# MSPM0G350X register map
Vendor: Texas Instruments; File version: This preliminary header file does not have a version number - build date: 2023-02-21 16:25:48
CPU: CM0 r0p1, little endian, MPU, no FPU, 3 interrupt priority bits
Registers are 32-bit, read-write, reset 0x0 unless marked. A register's access mark holds for its fields unless they carry their own. Offsets are from the block's base; [hi:lo] are bit positions; {n}, {i} and the like mark numbered series.

## CANFD0 (part 1 of 2) — PERIPHERALREGION
Base 0x40508000
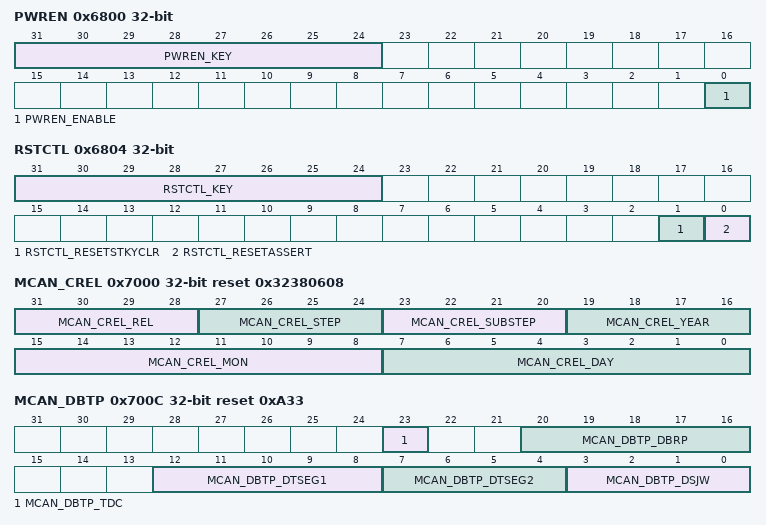
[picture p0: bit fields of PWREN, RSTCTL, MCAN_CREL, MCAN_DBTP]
0x6800 PWREN — Power enable
  [31:24] PWREN_KEY wo — KEY to allow Power State Change
    38=PWREN_KEY_UNLOCK_W (_TO_UNLOCK_W_)
  [0] PWREN_ENABLE — Enable the power
    0=PWREN_ENABLE_DISABLE (DISABLE); 1=PWREN_ENABLE_ENABLE (ENABLE)
0x6804 RSTCTL wo — Reset Control
  [31:24] RSTCTL_KEY — Unlock key
    177=RSTCTL_KEY_UNLOCK_W (_TO_UNLOCK_W_)
  [1] RSTCTL_RESETSTKYCLR — Clear the RESETSTKY bit in the STAT register
    0=RSTCTL_RESETSTKYCLR_NOP (NOP); 1=RSTCTL_RESETSTKYCLR_CLR (CLR)
  [0] RSTCTL_RESETASSERT — Assert reset to the peripheral
    0=RSTCTL_RESETASSERT_NOP (NOP); 1=RSTCTL_RESETASSERT_ASSERT (ASSERT)
0x6814 STAT ro — Status Register
  [16] STAT_RESETSTKY — This bit indicates, if the peripheral was reset, since this bit was cleared by RESETSTKYCLR in the RSTCTL register
    0=STAT_RESETSTKY_NORES (NORES); 1=STAT_RESETSTKY_RESET (RESET)
0x7000 MCAN_CREL ro reset 0x32380608 — MCAN Core Release Register
  [31:28] MCAN_CREL_REL — Core Release. One digit, BCD-coded.
  [27:24] MCAN_CREL_STEP — Step of Core Release. One digit, BCD-coded.
  [23:20] MCAN_CREL_SUBSTEP — Sub-Step of Core Release. One digit, BCD-coded.
  [19:16] MCAN_CREL_YEAR — Time Stamp Year. One digit, BCD-coded.
  [15:8] MCAN_CREL_MON — Time Stamp Month. Two digits, BCD-coded.
  [7:0] MCAN_CREL_DAY — Time Stamp Day. Two digits, BCD-coded.
0x7004 MCAN_ENDN ro reset 0x87654321 — MCAN Endian Register
  [31:0] MCAN_ENDN_ETV — Endianess Test Value. Reading the constant value maintained in this register allows software to determine the endianess of the host CPU.
0x700C MCAN_DBTP reset 0xA33 — MCAN Data Bit Timing and Prescaler Register
  [23] MCAN_DBTP_TDC — Transmitter Delay Compensation 0 Transmitter Delay Compensation disabled 1 Transmitter Delay Compensation enabled +I107
  [20:16] MCAN_DBTP_DBRP — Data Bit Rate Prescaler. The value by which the oscillator frequency is divided for generating the bit time quanta. The bit time is built up from a multiple of this quanta. Valid values for the Bit Rate Prescaler are 0 to 31. The actual interpretation by the hardware of this value is such that one more than the value programmed here is used. Qualified Write is possible only with CCCR.CCE='1' and CCCR.INIT='1'.
  [12:8] MCAN_DBTP_DTSEG1 — Data Time Segment Before Sample Point. Valid values are 0 to 31. The actual interpretation by the hardware of this value is such that one more than the programmed value is used. Qualified Write is possible only with CCCR.CCE='1' and CCCR.INIT='1'.
  [7:4] MCAN_DBTP_DTSEG2 — Data Time Segment After Sample Point. Valid values are 0 to 15. The actual interpretation by the hardware of this value is such that one more than the programmed value is used. Qualified Write is possible only with CCCR.CCE='1' and CCCR.INIT='1'.
  [3:0] MCAN_DBTP_DSJW — Data Resynchronization Jump Width. Valid values are 0 to 15. The actual interpretation by the hardware of this value is such that one more than the value programmed here is used. Qualified Write is possible only with CCCR.CCE='1' and CCCR.INIT='1'.
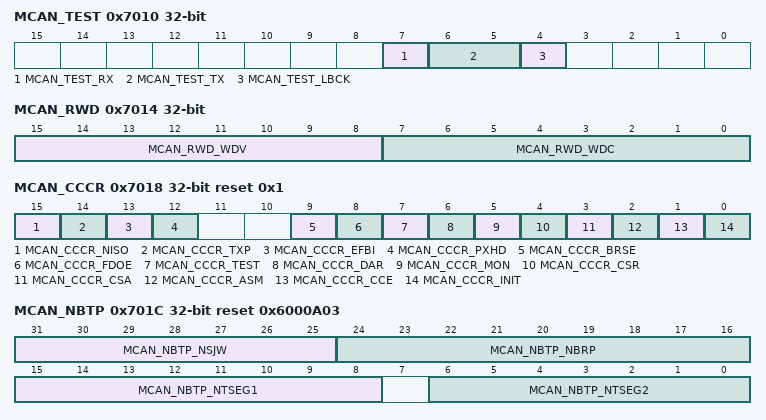
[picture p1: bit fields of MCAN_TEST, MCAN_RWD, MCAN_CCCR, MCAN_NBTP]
0x7010 MCAN_TEST (reset mask 0xFFFFFF7F)
  [7] MCAN_TEST_RX ro — Receive Pin. Monitors the actual value of the CAN receive pin. 0 The CAN bus is dominant (CAN RX pin = '0') 1 The CAN bus is recessive (CAN RX pin = '1')
  [6:5] MCAN_TEST_TX — Control of Transmit Pin 00 CAN TX pin controlled by the CAN Core, updated at the end of the CAN bit time 01 Sample Point can be monitored at CAN TX pin 10 Dominant ('0') level at CAN TX pin 11 Recessive ('1') at CAN TX pin Qualified Write is possible only with CCCR.CCE='1' and CCCR.INIT='1'.
  [4] MCAN_TEST_LBCK — Loop Back Mode 0 Reset value, Loop Back Mode is disabled 1 Loop Back Mode is enabled Qualified Write is possible only with CCCR.CCE='1' and CCCR.INIT='1'.
0x7014 MCAN_RWD — MCAN RAM Watchdog
  [15:8] MCAN_RWD_WDV ro — Watchdog Value. Acutal Message RAM Watchdog Counter Value. The RAM Watchdog monitors the READY output of the Message RAM. A Message RAM access via the MCAN's Generic Master Interface starts the Message RAM Watchdog Counter with the value configured by the WDC field. The counter is reloaded with WDC when the Message RAM signals successful completion by activating its READY output. In case there is no response from the Message RAM until the counter has counted down to zero, the counter stops and interrupt flag MCAN_IR.WDI is set. The RAM Watchdog Counter is clocked by the host (system) clock.
  [7:0] MCAN_RWD_WDC — Watchdog Configuration. Start value of the Message RAM Watchdog Counter. With the reset value of &quot;00&quot; the counter is disabled. Qualified Write is possible only with CCCR.CCE='1' and CCCR.INIT='1'.
0x7018 MCAN_CCCR reset 0x1 — MCAN CC Control Register
  [15] MCAN_CCCR_NISO — Non ISO Operation. If this bit is set, the MCAN uses the CAN FD frame format as specified by the Bosch CAN FD Specification V1.0. 0 CAN FD frame format according to ISO 11898-1:2015 1 CAN FD frame format according to Bosch CAN FD Specification V1.0
  [14] MCAN_CCCR_TXP — Transmit Pause. If this bit is set, the MCAN pauses for two CAN bit times before starting the next transmission after itself has successfully transmitted a frame. 0 Transmit pause disabled 1 Transmit pause enabled Qualified Write is possible only with CCCR.CCE='1' and CCCR.INIT='1'.
  [13] MCAN_CCCR_EFBI — Edge Filtering during Bus Integration 0 Edge filtering disabled 1 Two consecutive dominant tq required to detect an edge for hard synchronization Qualified Write is possible only with CCCR.CCE='1' and CCCR.INIT='1'.
  [12] MCAN_CCCR_PXHD — Protocol Exception Handling Disable 0 Protocol exception handling enabled 1 Protocol exception handling disabled Note: When protocol exception handling is disabled, the MCAN will transmit an error frame when it detects a protocol exception condition. Qualified Write is possible only with CCCR.CCE='1' and CCCR.INIT='1'.
  [9] MCAN_CCCR_BRSE — Bit Rate Switch Enable 0 Bit rate switching for transmissions disabled 1 Bit rate switching for transmissions enabled Note: When CAN FD operation is disabled FDOE = '0', BRSE is not evaluated. Qualified Write is possible only with CCCR.CCE='1' and CCCR.INIT='1'.
  [8] MCAN_CCCR_FDOE — Flexible Datarate Operation Enable 0 FD operation disabled 1 FD operation enabled Qualified Write is possible only with CCCR.CCE='1' and CCCR.INIT='1'.
  [7] MCAN_CCCR_TEST — Test Mode Enable 0 Normal operation, register TEST holds reset values 1 Test Mode, write access to register TEST enabled Qualified Write 1 to Set is possible only with CCCR.CCE='1' and CCCR.INIT='1'.
  [6] MCAN_CCCR_DAR — Disable Automatic Retransmission 0 Automatic retransmission of messages not transmitted successfully enabled 1 Automatic retransmission disabled Qualified Write is possible only with CCCR.CCE='1' and CCCR.INIT='1'.
  [5] MCAN_CCCR_MON — Bus Monitoring Mode. Bit MON can only be set by SW when both CCE and INIT are set to '1'. The bit can be reset by SW at any time. 0 Bus Monitoring Mode is disabled 1 Bus Monitoring Mode is enabled Qualified Write 1 to Set is possible only with CCCR.CCE='1' and CCCR.INIT='1'.
  [4] MCAN_CCCR_CSR — Clock Stop Request 0 No clock stop is requested 1 Clock stop requested. When clock stop is requested, first INIT and then CSA will be set after all pending transfer requests have been completed and the CAN bus reached idle.
  [3] MCAN_CCCR_CSA ro — Clock Stop Acknowledge 0 No clock stop acknowledged 1 MCAN may be set in power down by stopping the Host and CAN clocks
  [2] MCAN_CCCR_ASM — Restricted Operation Mode. Bit ASM can only be set by SW when both CCE and INIT are set to '1'. The bit can be reset by SW at any time. 0 Normal CAN operation 1 Restricted Operation Mode active Qualified Write 1 to Set is possible only with CCCR.CCE='1' and CCCR.INIT='1'.
  [1] MCAN_CCCR_CCE — Configuration Change Enable 0 The CPU has no write access to the protected configuration registers 1 The CPU has write access to the protected configuration registers (while CCCR.INIT = '1') Qualified Write is possible only with CCCR.CCE='1' and CCCR.INIT='1'.
  [0] MCAN_CCCR_INIT — Initialization 0 Normal Operation 1 Initialization is started Note: Due to the synchronization mechanism between the two clock domains, there may be a delay until the value written to INIT can be read back. Therefore the programmer has to assure that the previous value written to INIT has been accepted by reading INIT before setting INIT to a new value.
0x701C MCAN_NBTP reset 0x6000A03 — MCAN Nominal Bit Timing and Prescaler Register
  [31:25] MCAN_NBTP_NSJW — Nominal (Re)Synchronization Jump Width. Valid values are 0 to 127. The actual interpretation by the hardware of this value is such that one more than the value programmed here is used. Qualified Write is possible only with CCCR.CCE='1' and CCCR.INIT='1'.
  [24:16] MCAN_NBTP_NBRP — Nominal Bit Rate Prescaler. The value by which the oscillator frequency is divided for generating the bit time quanta. The bit time is built up from a multiple of this quanta. Valid values for the Bit Rate Prescaler are 0 to 511. The actual interpretation by the hardware of this value is such that one more than the value programmed here is used. Qualified Write is possible only with CCCR.CCE='1' and CCCR.INIT='1'.
  [15:8] MCAN_NBTP_NTSEG1 — Nominal Time Segment Before Sample Point. Valid values are 1 to 255. The actual interpretation by the hardware of this value is such that one more than the programmed value is used. Qualified Write is possible only with CCCR.CCE='1' and CCCR.INIT='1'.
  [6:0] MCAN_NBTP_NTSEG2 — Nominal Time Segment After Sample Point. Valid values are 1 to 127. The actual interpretation by the hardware of this value is such that one more than the programmed value is used. Qualified Write is possible only with CCCR.CCE='1' and CCCR.INIT='1'.
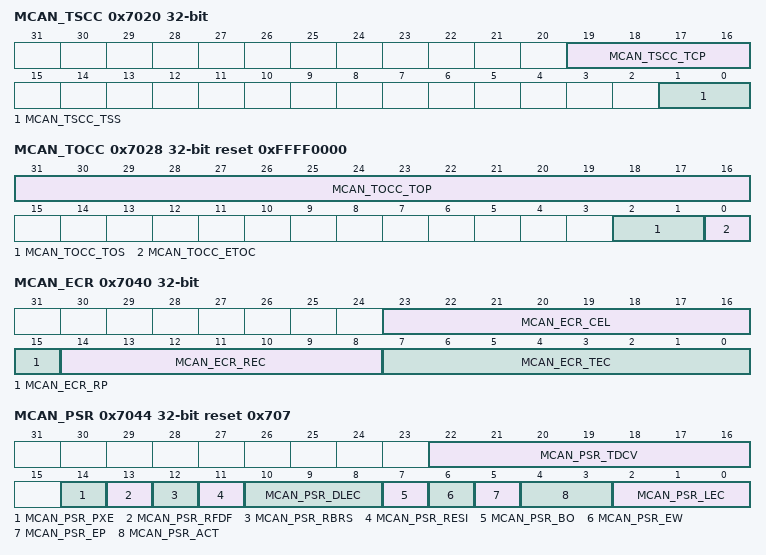
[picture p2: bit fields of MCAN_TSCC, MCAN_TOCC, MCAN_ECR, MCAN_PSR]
0x7020 MCAN_TSCC — MCAN Timestamp Counter Configuration
  [19:16] MCAN_TSCC_TCP — Timestamp Counter Prescaler. Configures the timestamp and timeout counters time unit in multiples of CAN bit times. Valid values are 0 to 15. The actual interpretation by the hardware of this value is such that one more than the value programmed here is used. Note: With CAN FD an external counter is required for timestamp generation (TSS = &quot;10&quot;). Qualified Write is possible only with CCCR.CCE='1' and CCCR.INIT='1'.
  [1:0] MCAN_TSCC_TSS — Timestamp Select 00 Timestamp counter value always 0x0000 01 Timestamp counter value incremented according to TCP 10 External timestamp counter value used 11 Same as &quot;00&quot; Qualified Write is possible only with CCCR.CCE='1' and CCCR.INIT='1'.
0x7024 MCAN_TSCV — MCAN Timestamp Counter Value
  [15:0] MCAN_TSCV_TSC — Timestamp Counter. The internal/external Timestamp Counter value is captured on start of frame (both Rx and Tx). When TSCC.TSS = &quot;01&quot;, the Timestamp Counter is incremented in multiples of CAN bit times, (1...16), depending on the configuration of TSCC.TCP. A wrap around sets interrupt flag IR.TSW. Write access resets the counter to zero. When TSCC.TSS = &quot;10&quot;, TSC reflects the External Timestamp Counter value, and a write access has no impact. Note: A &quot;wrap around&quot; is a change of the Timestamp Counter value from non-zero to zero not caused by write access to MCAN_TSCV.
0x7028 MCAN_TOCC reset 0xFFFF0000 — MCAN Timeout Counter Configuration
  [31:16] MCAN_TOCC_TOP — Timeout Period. Start value of the Timeout Counter (down-counter). Configures the Timeout Period. Qualified Write is possible only with CCCR.CCE='1' and CCCR.INIT='1'.
  [2:1] MCAN_TOCC_TOS — Timeout Select. When operating in Continuous mode, a write to TOCV presets the counter to the value configured by TOCC.TOP and continues down-counting. When the Timeout Counter is controlled by one of the FIFOs, an empty FIFO presets the counter to the value configured by TOCC.TOP. Down-counting is started when the first FIFO element is stored. 00 Continuous operation 01 Timeout controlled by Tx Event FIFO 10 Timeout controlled by Rx FIFO 0 11 Timeout controlled by Rx FIFO 1 Qualified Write is possible only with CCCR.CCE='1' and CCCR.INIT='1'.
  [0] MCAN_TOCC_ETOC — Enable Timeout Counter 0 Timeout Counter disabled 1 Timeout Counter enabled Qualified Write is possible only with CCCR.CCE='1' and CCCR.INIT='1'.
0x702C MCAN_TOCV reset 0xFFFF — MCAN Timeout Counter Value
  [15:0] MCAN_TOCV_TOC — Timeout Counter. The Timeout Counter is decremented in multiples of CAN bit times, (1...16), depending on the configuration of TSCC.TCP. When decremented to zero, interrupt flag IR.TOO is set and the Timeout Counter is stopped. Start and reset/restart conditions are configured via TOCC.TOS.
0x7040 MCAN_ECR ro — MCAN Error Counter Register
  [23:16] MCAN_ECR_CEL — CAN Error Logging. The counter is incremented each time when a CAN protocol error causes the Transmit Error Counter or the Receive Error Counter to be incremented. It is reset by read access to CEL. The counter stops at 0xFF; the next increment of TEC or REC sets interrupt flag IR.ELO. Note: When CCCR.ASM is set, the CAN protocol controller does not increment TEC and REC when a CAN protocol error is detected, but CEL is still incremented.
  [15] MCAN_ECR_RP — Receive Error Passive 0 The Receive Error Counter is below the error passive level of 128 1 The Receive Error Counter has reached the error passive level of 128
  [14:8] MCAN_ECR_REC — Receive Error Counter. Actual state of the Receive Error Counter, values between 0 and 127. Note: When CCCR.ASM is set, the CAN protocol controller does not increment TEC and REC when a CAN protocol error is detected, but CEL is still incremented.
  [7:0] MCAN_ECR_TEC — Transmit Error Counter. Actual state of the Transmit Error Counter, values between 0 and 255. Note: When CCCR.ASM is set, the CAN protocol controller does not increment TEC and REC when a CAN protocol error is detected, but CEL is still incremented.
0x7044 MCAN_PSR ro reset 0x707 — MCAN Protocol Status Register
  [22:16] MCAN_PSR_TDCV — Transmitter Delay Compensation Value. Position of the secondary sample point, defined by the sum of the measured delay from the internal CAN TX signal to the internal CAN RX signal and TDCR.TDCO. The SSP position is, in the data phase, the number of mtq between the start of the transmitted bit and the secondary sample point. Valid values are 0 to 127 mtq.
  [14] MCAN_PSR_PXE — Protocol Exception Event 0 No protocol exception event occurred since last read access 1 Protocol exception event occurred
  [13] MCAN_PSR_RFDF — Received a CAN FD Message. This bit is set independent of acceptance filtering. 0 Since this bit was reset by the CPU, no CAN FD message has been received 1 Message in CAN FD format with FDF flag set has been received
  [12] MCAN_PSR_RBRS — BRS Flag of Last Received CAN FD Message. This bit is set together with RFDF, independent of acceptance filtering. 0 Last received CAN FD message did not have its BRS flag set 1 Last received CAN FD message had its BRS flag set
  [11] MCAN_PSR_RESI — ESI Flag of Last Received CAN FD Message. This bit is set together with RFDF, independent of acceptance filtering. 0 Last received CAN FD message did not have its ESI flag set 1 Last received CAN FD message had its ESI flag set
  [10:8] MCAN_PSR_DLEC — Data Phase Last Error Code. Type of last error that occurred in the data phase of a CAN FD format frame with its BRS flag set. Coding is the same as for LEC. This field will be cleared to zero when a CAN FD format frame with its BRS flag set has been transferred (reception or transmission) without error.
  [7] MCAN_PSR_BO — Bus_Off Status 0 The M_CAN is not Bus_Off 1 The M_CAN is in Bus_Off state
  [6] MCAN_PSR_EW — Warning Status 0 Both error counters are below the Error_Warning limit of 96 1 At least one of error counter has reached the Error_Warning limit of 96
  [5] MCAN_PSR_EP — Error Passive 0 The M_CAN is in the Error_Active state. It normally takes part in bus communication and sends an active error flag when an error has been detected 1 The M_CAN is in the Error_Passive state
  [4:3] MCAN_PSR_ACT — Node Activity. Monitors the module's CAN communication state. 00 Synchronizing - node is synchronizing on CAN communication 01 Idle - node is neither receiver nor transmitter 10 Receiver - node is operating as receiver 11 Transmitter - node is operating as transmitter Note: ACT is set to &quot;00&quot; by a Protocol Exception Event.
  [2:0] MCAN_PSR_LEC — Last Error Code. The LEC indicates the type of the last error to occur on the CAN bus. This field will be cleared to '0' when a message has been transferred (reception or transmission) without error. 0 No Error: No error occurred since LEC has been reset by successful reception or transmission. 1 Stuff Error: More than 5 equal bits in a sequence have occurred in a part of a received message where this is not allowed. 2 Form Error: A fixed format part of a received frame has the wrong format. 3 AckError: The message transmitted by the MCAN was not acknowledged by another node. 4 Bit1Error: During the transmission of a message (with the exception of the arbitration field), the device wanted to send a recessive level (bit of logical value '1'), but the monitored bus value was dominant. 5 Bit0Error: During the transmission of a message (or acknowledge bit, or active error flag, or overload flag), the device wanted to send a dominant level (data or identifier bit logical value '0'), but the monitored bus value was recessive. During Bus_Off recovery this status is set each time a sequence of 11 recessive bits has been monitored. This enables the CPU to monitor the proceeding of the Bus_Off recovery sequence (indicating the bus is not stuck at dominant or continuously disturbed). 6 CRCError: The CRC check sum of a received message was incorrect. The CRC of an incoming message does not match with the CRC calculated from the received data. 7 NoChange: Any read access to the Protocol Status Register re-initializes the LEC to '7'. When the LEC shows the value '7', no CAN bus event was detected since the last CPU read access to the Protocol Status Register. Note: When a frame in CAN FD format has reached the data phase with BRS flag set, the next CAN event (error or valid frame) will be shown in DLEC instead of LEC. An error in a fixed stuff bit of a CAN FD CRC sequence will be shown as a Form Error, not Stuff Error. Note: The Bus_Off recovery sequence (see ISO 11898-1:2015) cannot be shortened by setting or resetting CCCR.INIT. If the device goes Bus_Off, it will set CCCR.INIT of its own accord, stopping all bus activities. Once CCCR.INIT has been cleared by the CPU, the device will then wait for 129 occurrences of Bus Idle (129 * 11 consecutive recessive bits) before resuming normal operation. At the end of the Bus_Off recovery sequence, the Error Management Counters will be reset. During the waiting time after the resetting of CCCR.INIT, each time a sequence of 11 recessive bits has been monitored, a Bit0Error code is written to PSR.LEC, enabling the CPU to readily check up whether the CAN bus is stuck at dominant or continuously disturbed and to monitor the Bus_Off recovery sequence. ECR.REC is used to count these sequences.
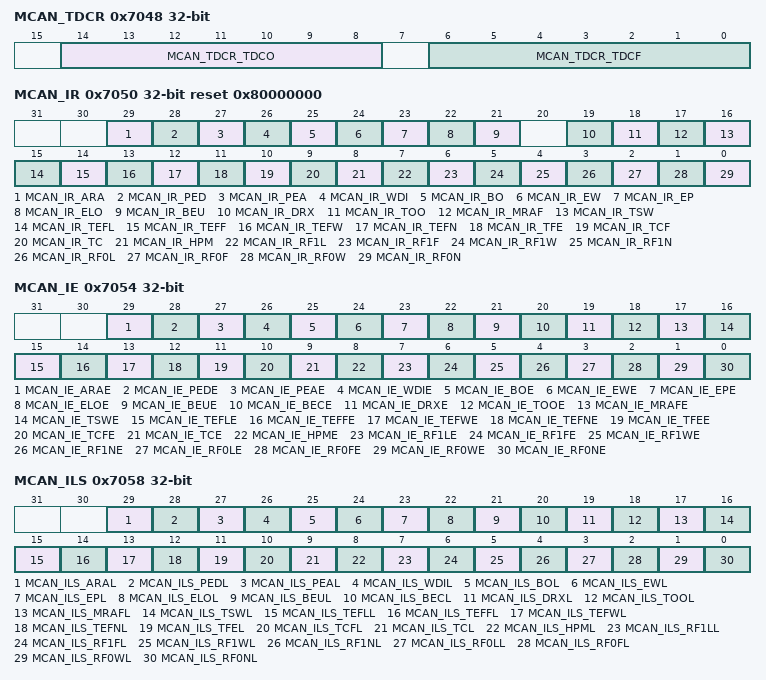
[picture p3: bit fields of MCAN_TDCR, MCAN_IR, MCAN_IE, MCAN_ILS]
0x7048 MCAN_TDCR — MCAN Transmitter Delay Compensation Register
  [14:8] MCAN_TDCR_TDCO — Transmitter Delay Compensation Offset. Offset value defining the distance between the measured delay from the internal CAN TX signal to the internal CAN RX signal and the secondary sample point. Valid values are 0 to 127 mtq. Qualified Write is possible only with CCCR.CCE='1' and CCCR.INIT='1'.
  [6:0] MCAN_TDCR_TDCF — Transmitter Delay Compensation Filter Window Length. Defines the minimum value for the SSP position, dominant edges on the internal CAN RX signal that would result in an earlier SSP position are ignored for transmitter delay measurement. The feature is enabled when TDCF is configured to a value greater than TDCO. Valid values are 0 to 127 mtq. Qualified Write is possible only with CCCR.CCE='1' and CCCR.INIT='1'.
0x7050 MCAN_IR reset 0x80000000 — MCAN Interrupt Register
  [29] MCAN_IR_ARA — Access to Reserved Address 0 No access to reserved address occurred 1 Access to reserved address occurred
  [28] MCAN_IR_PED — Protocol Error in Data Phase (Data Bit Time is used) 0 No protocol error in data phase 1 Protocol error in data phase detected (PSR.DLEC ? 0,7)
  [27] MCAN_IR_PEA — Protocol Error in Arbitration Phase (Nominal Bit Time is used) 0 No protocol error in arbitration phase 1 Protocol error in arbitration phase detected (PSR.LEC ? 0,7)
  [26] MCAN_IR_WDI — Watchdog Interrupt 0 No Message RAM Watchdog event occurred 1 Message RAM Watchdog event due to missing READY
  [25] MCAN_IR_BO — Bus_Off Status 0 Bus_Off status unchanged 1 Bus_Off status changed
  [24] MCAN_IR_EW — Warning Status 0 Error_Warning status unchanged 1 Error_Warning status changed
  [23] MCAN_IR_EP — Error Passive 0 Error_Passive status unchanged 1 Error_Passive status changed
  [22] MCAN_IR_ELO — Error Logging Overflow 0 CAN Error Logging Counter did not overflow 1 Overflow of CAN Error Logging Counter occurred
  [21] MCAN_IR_BEU — Bit Error Uncorrected. Message RAM bit error detected, uncorrected. This bit is set when a double bit error is detected by the ECC aggregator attached to the Message RAM. An uncorrected Message RAM bit error sets CCCR.INIT to '1'. This is done to avoid transmission of corrupted data. 0 No bit error detected when reading from Message RAM 1 Bit error detected, uncorrected (e.g. parity logic)
  [19] MCAN_IR_DRX — Message Stored to Dedicated Rx Buffer. The flag is set whenever a received message has been stored into a dedicated Rx Buffer. 0 No Rx Buffer updated 1 At least one received message stored into an Rx Buffer
  [18] MCAN_IR_TOO — Timeout Occurred 0 No timeout 1 Timeout reached
  [17] MCAN_IR_MRAF — Message RAM Access Failure. The flag is set, when the Rx Handler: - has not completed acceptance filtering or storage of an accepted message until the arbitration field of the following message has been received. In this case acceptance filtering or message storage is aborted and the Rx Handler starts processing of the following message. - was not able to write a message to the Message RAM. In this case message storage is aborted. In both cases the FIFO put index is not updated resp. the New Data flag for a dedicated Rx Buffer is not set, a partly stored message is overwritten when the next message is stored to this location. The flag is also set when the Tx Handler was not able to read a message from the Message RAM in time. In this case message transmission is aborted. In case of a Tx Handler access failure the MCAN is switched into Restricted Operation Mode. To leave Restricted Operation Mode, the Host CPU has to reset CCCR.ASM. 0 No Message RAM access failure occurred 1 Message RAM access failure occurred
  [16] MCAN_IR_TSW — Timestamp Wraparound 0 No timestamp counter wrap-around 1 Timestamp counter wrapped around
  [15] MCAN_IR_TEFL — Tx Event FIFO Element Lost 0 No Tx Event FIFO element lost 1 Tx Event FIFO element lost, also set after write attempt to Tx Event FIFO of size zero
  [14] MCAN_IR_TEFF — Tx Event FIFO Full 0 Tx Event FIFO not full 1 Tx Event FIFO full
  [13] MCAN_IR_TEFW — Tx Event FIFO Watermark Reached 0 Tx Event FIFO fill level below watermark 1 Tx Event FIFO fill level reached watermark
  [12] MCAN_IR_TEFN — Tx Event FIFO New Entry 0 Tx Event FIFO unchanged 1 Tx Handler wrote Tx Event FIFO element
  [11] MCAN_IR_TFE — Tx FIFO Empty 0 Tx FIFO non-empty 1 Tx FIFO empty
  [10] MCAN_IR_TCF — Transmission Cancellation Finished 0 No transmission cancellation finished 1 Transmission cancellation finished
  [9] MCAN_IR_TC — Transmission Completed 0 No transmission completed 1 Transmission completed
  [8] MCAN_IR_HPM — High Priority Message 0 No high priority message received 1 High priority message received
  [7] MCAN_IR_RF1L — Rx FIFO 1 Message Lost 0 No Rx FIFO 1 message lost 1 Rx FIFO 1 message lost, also set after write attempt to Rx FIFO 1 of size zero
  [6] MCAN_IR_RF1F — Rx FIFO 1 Full 0 Rx FIFO 1 not full 1 Rx FIFO 1 full
  [5] MCAN_IR_RF1W — Rx FIFO 1 Watermark Reached 0 Rx FIFO 1 fill level below watermark 1 Rx FIFO 1 fill level reached watermark
  [4] MCAN_IR_RF1N — Rx FIFO 1 New Message 0 No new message written to Rx FIFO 1 1 New message written to Rx FIFO 1
  [3] MCAN_IR_RF0L — Rx FIFO 0 Message Lost 0 No Rx FIFO 0 message lost 1 Rx FIFO 0 message lost, also set after write attempt to Rx FIFO 0 of size zero
  [2] MCAN_IR_RF0F — Rx FIFO 0 Full 0 Rx FIFO 0 not full 1 Rx FIFO 0 full
  [1] MCAN_IR_RF0W — Rx FIFO 0 Watermark Reached 0 Rx FIFO 0 fill level below watermark 1 Rx FIFO 0 fill level reached watermark
  [0] MCAN_IR_RF0N — Rx FIFO 0 New Message 0 No new message written to Rx FIFO 0 1 New message written to Rx FIFO 0
0x7054 MCAN_IE — MCAN Interrupt Enable
  [29] MCAN_IE_ARAE — Access to Reserved Address Enable
  [28] MCAN_IE_PEDE — Protocol Error in Data Phase Enable
  [27] MCAN_IE_PEAE — Protocol Error in Arbitration Phase Enable
  [26] MCAN_IE_WDIE — Watchdog Interrupt Enable
  [25] MCAN_IE_BOE — Bus_Off Status Enable
  [24] MCAN_IE_EWE — Warning Status Enable
  [23] MCAN_IE_EPE — Error Passive Enable
  [22] MCAN_IE_ELOE — Error Logging Overflow Enable
  [21] MCAN_IE_BEUE — Bit Error Uncorrected Enable
  [20] MCAN_IE_BECE — Bit Error Corrected Enable A separate interrupt line reserved for corrected bit errors is provided via the MCAN_ERROR_REGS. It advised for the user to use these registers and leave this bit cleared to '0'.
  [19] MCAN_IE_DRXE — Message Stored to Dedicated Rx Buffer Enable
  [18] MCAN_IE_TOOE — Timeout Occurred Enable
  [17] MCAN_IE_MRAFE — Message RAM Access Failure Enable
  [16] MCAN_IE_TSWE — Timestamp Wraparound Enable
  [15] MCAN_IE_TEFLE — Tx Event FIFO Element Lost Enable
  [14] MCAN_IE_TEFFE — Tx Event FIFO Full Enable
  [13] MCAN_IE_TEFWE — Tx Event FIFO Watermark Reached Enable
  [12] MCAN_IE_TEFNE — Tx Event FIFO New Entry Enable
  [11] MCAN_IE_TFEE — Tx FIFO Empty Enable
  [10] MCAN_IE_TCFE — Transmission Cancellation Finished Enable
  [9] MCAN_IE_TCE — Transmission Completed Enable
  [8] MCAN_IE_HPME — High Priority Message Enable
  [7] MCAN_IE_RF1LE — Rx FIFO 1 Message Lost Enable
  [6] MCAN_IE_RF1FE — Rx FIFO 1 Full Enable
  [5] MCAN_IE_RF1WE — Rx FIFO 1 Watermark Reached Enable
  [4] MCAN_IE_RF1NE — Rx FIFO 1 New Message Enable
  [3] MCAN_IE_RF0LE — Rx FIFO 0 Message Lost Enable
  [2] MCAN_IE_RF0FE — Rx FIFO 0 Full Enable
  [1] MCAN_IE_RF0WE — Rx FIFO 0 Watermark Reached Enable
  [0] MCAN_IE_RF0NE — Rx FIFO 0 New Message Enable
0x7058 MCAN_ILS — MCAN Interrupt Line Select
  [29] MCAN_ILS_ARAL — Access to Reserved Address Line 0 Interrupt source is assigned to Interrupt Line 0 1 Interrupt source is assigned to Interrupt Line 1
  [28] MCAN_ILS_PEDL — Protocol Error in Data Phase Line 0 Interrupt source is assigned to Interrupt Line 0 1 Interrupt source is assigned to Interrupt Line 1
  [27] MCAN_ILS_PEAL — Protocol Error in Arbitration Phase Line 0 Interrupt source is assigned to Interrupt Line 0 1 Interrupt source is assigned to Interrupt Line 1
  [26] MCAN_ILS_WDIL — Watchdog Interrupt Line 0 Interrupt source is assigned to Interrupt Line 0 1 Interrupt source is assigned to Interrupt Line 1
  [25] MCAN_ILS_BOL — Bus_Off Status Line 0 Interrupt source is assigned to Interrupt Line 0 1 Interrupt source is assigned to Interrupt Line 1
  [24] MCAN_ILS_EWL — Warning Status Line 0 Interrupt source is assigned to Interrupt Line 0 1 Interrupt source is assigned to Interrupt Line 1
  [23] MCAN_ILS_EPL — Error Passive Line 0 Interrupt source is assigned to Interrupt Line 0 1 Interrupt source is assigned to Interrupt Line 1
  [22] MCAN_ILS_ELOL — Error Logging Overflow Line 0 Interrupt source is assigned to Interrupt Line 0 1 Interrupt source is assigned to Interrupt Line 1
  [21] MCAN_ILS_BEUL — Bit Error Uncorrected Line 0 Interrupt source is assigned to Interrupt Line 0 1 Interrupt source is assigned to Interrupt Line 1
  [20] MCAN_ILS_BECL — Bit Error Corrected Line A separate interrupt line reserved for corrected bit errors is provided via the MCAN_ERROR_REGS. It advised for the user to use these registers and leave the MCAN_IE.BECE bit cleared to '0' (disabled), thereby relegating this bit to not applicable.
  [19] MCAN_ILS_DRXL — Message Stored to Dedicated Rx Buffer Line 0 Interrupt source is assigned to Interrupt Line 0 1 Interrupt source is assigned to Interrupt Line 1
  [18] MCAN_ILS_TOOL — Timeout Occurred Line 0 Interrupt source is assigned to Interrupt Line 0 1 Interrupt source is assigned to Interrupt Line 1
  [17] MCAN_ILS_MRAFL — Message RAM Access Failure Line 0 Interrupt source is assigned to Interrupt Line 0 1 Interrupt source is assigned to Interrupt Line 1
  [16] MCAN_ILS_TSWL — Timestamp Wraparound Line 0 Interrupt source is assigned to Interrupt Line 0 1 Interrupt source is assigned to Interrupt Line 1
  [15] MCAN_ILS_TEFLL — Tx Event FIFO Element Lost Line 0 Interrupt source is assigned to Interrupt Line 0 1 Interrupt source is assigned to Interrupt Line 1
  [14] MCAN_ILS_TEFFL — Tx Event FIFO Full Line 0 Interrupt source is assigned to Interrupt Line 0 1 Interrupt source is assigned to Interrupt Line 1
  [13] MCAN_ILS_TEFWL — Tx Event FIFO Watermark Reached Line 0 Interrupt source is assigned to Interrupt Line 0 1 Interrupt source is assigned to Interrupt Line 1
  [12] MCAN_ILS_TEFNL — Tx Event FIFO New Entry Line 0 Interrupt source is assigned to Interrupt Line 0 1 Interrupt source is assigned to Interrupt Line 1
  [11] MCAN_ILS_TFEL — Tx FIFO Empty Line 0 Interrupt source is assigned to Interrupt Line 0 1 Interrupt source is assigned to Interrupt Line 1
  [10] MCAN_ILS_TCFL — Transmission Cancellation Finished Line 0 Interrupt source is assigned to Interrupt Line 0 1 Interrupt source is assigned to Interrupt Line 1
  [9] MCAN_ILS_TCL — Transmission Completed Line 0 Interrupt source is assigned to Interrupt Line 0 1 Interrupt source is assigned to Interrupt Line 1
  [8] MCAN_ILS_HPML — High Priority Message Line 0 Interrupt source is assigned to Interrupt Line 0 1 Interrupt source is assigned to Interrupt Line 1
  [7] MCAN_ILS_RF1LL — Rx FIFO 1 Message Lost Line 0 Interrupt source is assigned to Interrupt Line 0 1 Interrupt source is assigned to Interrupt Line 1
  [6] MCAN_ILS_RF1FL — Rx FIFO 1 Full Line 0 Interrupt source is assigned to Interrupt Line 0 1 Interrupt source is assigned to Interrupt Line 1
  [5] MCAN_ILS_RF1WL — Rx FIFO 1 Watermark Reached Line 0 Interrupt source is assigned to Interrupt Line 0 1 Interrupt source is assigned to Interrupt Line 1
  [4] MCAN_ILS_RF1NL — Rx FIFO 1 New Message Line 0 Interrupt source is assigned to Interrupt Line 0 1 Interrupt source is assigned to Interrupt Line 1
  [3] MCAN_ILS_RF0LL — Rx FIFO 0 Message Lost Line 0 Interrupt source is assigned to Interrupt Line 0 1 Interrupt source is assigned to Interrupt Line 1
  [2] MCAN_ILS_RF0FL — Rx FIFO 0 Full Line 0 Interrupt source is assigned to Interrupt Line 0 1 Interrupt source is assigned to Interrupt Line 1
  [1] MCAN_ILS_RF0WL — Rx FIFO 0 Watermark Reached Line 0 Interrupt source is assigned to Interrupt Line 0 1 Interrupt source is assigned to Interrupt Line 1
  [0] MCAN_ILS_RF0NL — Rx FIFO 0 New Message Line 0 Interrupt source is assigned to Interrupt Line 0 1 Interrupt source is assigned to Interrupt Line 1
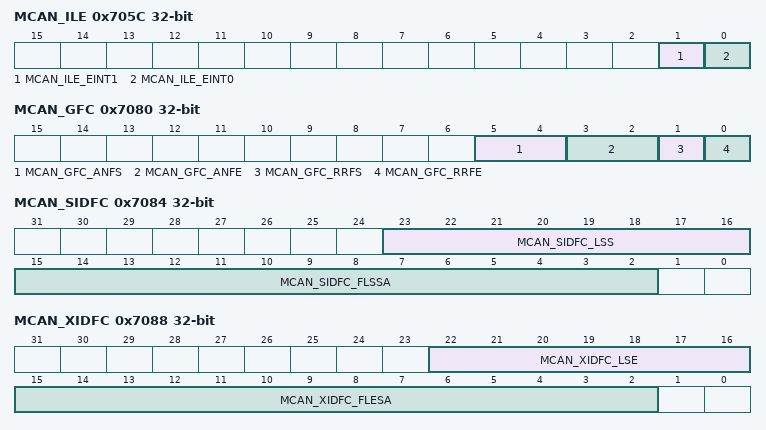
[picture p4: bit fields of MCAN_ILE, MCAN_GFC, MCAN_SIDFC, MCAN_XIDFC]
0x705C MCAN_ILE — MCAN Interrupt Line Enable
  [1] MCAN_ILE_EINT1 — Enable Interrupt Line 1 0 Interrupt Line 1 is disabled 1 Interrupt Line 1 is enabled
  [0] MCAN_ILE_EINT0 — Enable Interrupt Line 0 0 Interrupt Line 0 is disabled 1 Interrupt Line 0 is enabled
0x7080 MCAN_GFC — MCAN Global Filter Configuration
  [5:4] MCAN_GFC_ANFS — Accept Non-matching Frames Standard. Defines how received messages with 11-bit IDs that do not match any element of the filter list are treated. 00 Accept in Rx FIFO 0 01 Accept in Rx FIFO 1 10 Reject 11 Reject Qualified Write is possible only with CCCR.CCE='1' and CCCR.INIT='1'.
  [3:2] MCAN_GFC_ANFE — Accept Non-matching Frames Extended. Defines how received messages with 29-bit IDs that do not match any element of the filter list are treated. 00 Accept in Rx FIFO 0 01 Accept in Rx FIFO 1 10 Reject 11 Reject Qualified Write is possible only with CCCR.CCE='1' and CCCR.INIT='1'.
  [1] MCAN_GFC_RRFS — Reject Remote Frames Standard 0 Filter remote frames with 11-bit standard IDs 1 Reject all remote frames with 11-bit standard IDs Qualified Write is possible only with CCCR.CCE='1' and CCCR.INIT='1'.
  [0] MCAN_GFC_RRFE — Reject Remote Frames Extended 0 Filter remote frames with 29-bit extended IDs 1 Reject all remote frames with 29-bit extended IDs Qualified Write is possible only with CCCR.CCE='1' and CCCR.INIT='1'.
0x7084 MCAN_SIDFC — MCAN Standard ID Filter Configuration
  [23:16] MCAN_SIDFC_LSS — List Size Standard 0 No standard Message ID filter 1-128 Number of standard Message ID filter elements >128 Values greater than 128 are interpreted as 128
  [15:2] MCAN_SIDFC_FLSSA — Filter List Standard Start Address. Start address of standard Message ID filter list (32-bit word address).
0x7088 MCAN_XIDFC — MCAN Extended ID Filter Configuration
  [22:16] MCAN_XIDFC_LSE — Filter List Extended Start Address. Start address of extended Message ID filter list (32-bit word address). Qualified Write is possible only with CCCR.CCE='1' and CCCR.INIT='1'.
  [15:2] MCAN_XIDFC_FLESA — List Size Extended 0 No extended Message ID filter 1-64 Number of extended Message ID filter elements >64 Values greater than 64 are interpreted as 64 Qualified Write is possible only with CCCR.CCE='1' and CCCR.INIT='1'.
0x7090 MCAN_XIDAM reset 0x1FFFFFFF — MCAN Extended ID and Mask
  [28:0] MCAN_XIDAM_EIDM — Extended ID Mask. For acceptance filtering of extended frames the Extended ID AND Mask is ANDed with the Message ID of a received frame. Intended for masking of 29-bit IDs in SAE J1939. With the reset value of all bits set to one the mask is not active. Qualified Write is possible only with CCCR.CCE='1' and CCCR.INIT='1'.
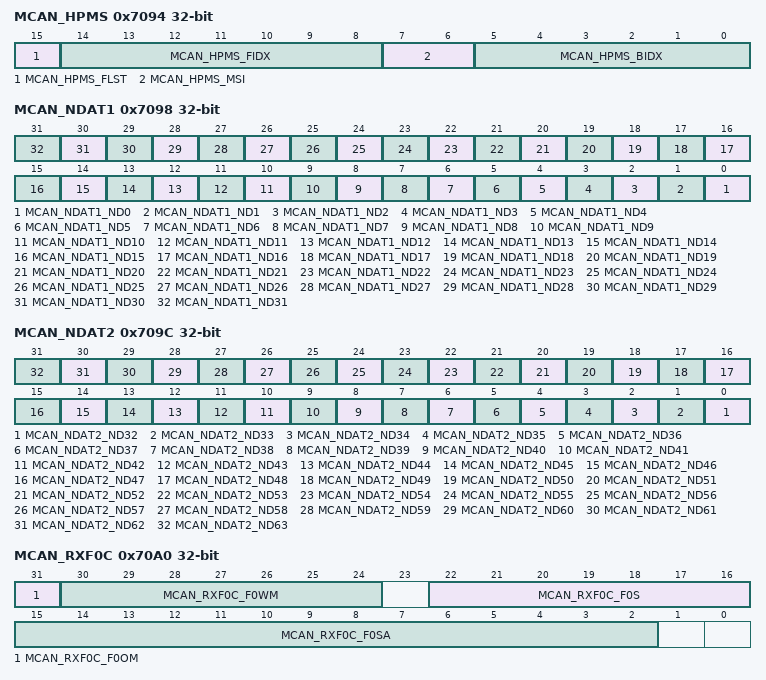
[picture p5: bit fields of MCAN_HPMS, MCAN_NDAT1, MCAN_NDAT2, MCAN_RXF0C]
0x7094 MCAN_HPMS ro — MCAN High Priority Message Status
  [15] MCAN_HPMS_FLST — Filter List. Indicates the filter list of the matching filter element. 0 Standard Filter List 1 Extended Filter List
  [14:8] MCAN_HPMS_FIDX — Filter Index. Index of matching filter element. Range is 0 to SIDFC.LSS - 1 resp. XIDFC.LSE - 1.
  [7:6] MCAN_HPMS_MSI — Message Storage Indicator 00 No FIFO selected 01 FIFO message lost 10 Message stored in FIFO 0 11 Message stored in FIFO 1
  [5:0] MCAN_HPMS_BIDX — Buffer Index. Index of Rx FIFO element to which the message was stored. Only valid when MSI(1) = '1'.
0x7098 MCAN_NDAT1 — MCAN New Data 1
  [n] MCAN_NDAT1_ND{n} (n=0..31) — New Data RX Buffer {n} 0 Rx Buffer not updated 1 Rx Buffer updated from new message
0x709C MCAN_NDAT2 — MCAN New Data 2
  [n-32] MCAN_NDAT2_ND{n} (n=32..63) — New Data RX Buffer {n} 0 Rx Buffer not updated 1 Rx Buffer updated from new message
0x70A0 MCAN_RXF0C — MCAN Rx FIFO 0 Configuration
  [31] MCAN_RXF0C_F0OM — FIFO 0 Operation Mode. FIFO 0 can be operated in blocking or in overwrite mode. 0 FIFO 0 blocking mode 1 FIFO 0 overwrite mode Qualified Write is possible only with CCCR.CCE='1' and CCCR.INIT='1'.
  [30:24] MCAN_RXF0C_F0WM — Rx FIFO 0 Watermark 0 Watermark interrupt disabled 1-64 Level for Rx FIFO 0 watermark interrupt (IR.RF0W) >64 Watermark interrupt disabled Qualified Write is possible only with CCCR.CCE='1' and CCCR.INIT='1'.
  [22:16] MCAN_RXF0C_F0S — Rx FIFO 0 Size. The Rx FIFO 0 elements are indexed from 0 to F0S-1. 0 No Rx FIFO 0 1-64 Number of Rx FIFO 0 elements >64 Values greater than 64 are interpreted as 64 Qualified Write is possible only with CCCR.CCE='1' and CCCR.INIT='1'.
  [15:2] MCAN_RXF0C_F0SA — Rx FIFO 0 Start Address. Start address of Rx FIFO 0 in Message RAM (32-bit word address). Qualified Write is possible only with CCCR.CCE='1' and CCCR.INIT='1'.
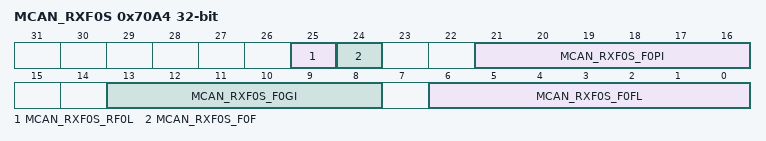
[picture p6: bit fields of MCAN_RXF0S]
0x70A4 MCAN_RXF0S ro — MCAN Rx FIFO 0 Status
  [25] MCAN_RXF0S_RF0L — Rx FIFO 0 Message Lost. This bit is a copy of interrupt flag IR.RF0L. When IR.RF0L is reset, this bit is also reset. 0 No Rx FIFO 0 message lost 1 Rx FIFO 0 message lost, also set after write attempt to Rx FIFO 0 of size zero Note: Overwriting the oldest message when RXF0C.F0OM = '1' will not set this flag.
  [24] MCAN_RXF0S_F0F — Rx FIFO 0 Full 0 Rx FIFO 0 not full 1 Rx FIFO 0 full
  [21:16] MCAN_RXF0S_F0PI — Rx FIFO 0 Put Index. Rx FIFO 0 write index pointer, range 0 to 63.
  [13:8] MCAN_RXF0S_F0GI — Rx FIFO 0 Get Index. Rx FIFO 0 read index pointer, range 0 to 63.
  [6:0] MCAN_RXF0S_F0FL — Rx FIFO 0 Fill Level. Number of elements stored in Rx FIFO 0, range 0 to 64.
0x70A8 MCAN_RXF0A — MCAN Rx FIFO 0 Acknowledge
  [5:0] MCAN_RXF0A_F0AI — Rx FIFO 0 Acknowledge Index. After the Host has read a message or a sequence of messages from Rx FIFO 0 it has to write the buffer index of the last element read from Rx FIFO 0 to F0AI. This will set the Rx FIFO 0 Get Index RXF0S.F0GI to F0AI + 1 and update the FIFO 0 Fill Level RXF0S.F0FL.
0x70AC MCAN_RXBC — MCAN Rx Buffer Configuration
  [15:2] MCAN_RXBC_RBSA — Rx Buffer Start Address. Configures the start address of the Rx Buffers section in the Message RAM (32-bit word address). +I466
